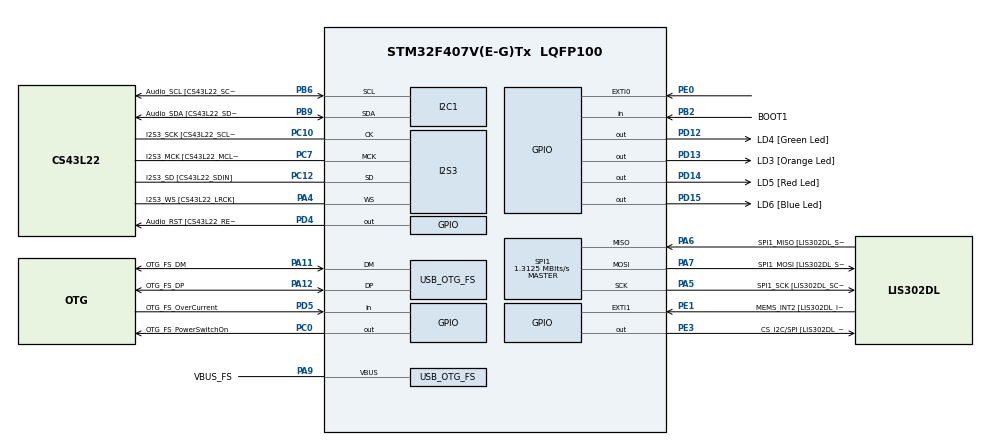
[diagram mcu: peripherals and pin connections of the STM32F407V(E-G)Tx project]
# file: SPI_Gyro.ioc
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FREERTOS.Tasks01=defaultTask,0,128,StartDefaultTask,Default,NULL
I2S3.AudioFreq-Half_Duplex_Master=I2S_AUDIOFREQ_96K
I2S3.ErrorAudioFreq=-2.34 %
I2S3.ErrorAudioFreq-Half_Duplex_Master=0.8 %
I2S3.FullDuplexMode=I2S_FULLDUPLEXMODE_DISABLE
I2S3.Instance=SPI$Index
I2S3.RealAudioFreq=93.75 KHz
I2S3.RealAudioFreq-Half_Duplex_Master=96.774 KHz
I2S3.VirtualMode=I2S_MODE_MASTER
Mcu.Family=STM32F4
Mcu.Name=STM32F407V(E-G)Tx
Mcu.Package=LQFP100
NVIC.EXTI0_IRQn=true\:5\:0\:false\:false\:true\:true\:true
NVIC.OTG_FS_IRQn=true\:5\:0\:false\:false\:true\:true\:true
NVIC.PriorityGroup=NVIC_PRIORITYGROUP_4
NVIC.TIM1_UP_TIM10_IRQn=true\:0\:0\:false\:false\:true\:false\:false
NVIC.TimeBase=TIM1_UP_TIM10_IRQn
NVIC.TimeBaseIP=TIM1
PA10.GPIO_Label=OTG_FS_ID
PA10.GPIO_Mode=GPIO_MODE_AF_PP
PA10.GPIO_PuPd=GPIO_NOPULL
PA10.GPIO_Speed=GPIO_SPEED_FREQ_LOW
PA10.Signal=USB_OTG_FS_ID
PA11.GPIO_Label=OTG_FS_DM
PA11.GPIO_Mode=GPIO_MODE_AF_PP
PA11.GPIO_PuPd=GPIO_NOPULL
PA11.GPIO_Speed=GPIO_SPEED_FREQ_LOW
PA11.Mode=Host_Only
PA11.Signal=USB_OTG_FS_DM
PA12.GPIO_Label=OTG_FS_DP
PA12.GPIO_Mode=GPIO_MODE_AF_PP
PA12.GPIO_PuPd=GPIO_NOPULL
PA12.GPIO_Speed=GPIO_SPEED_FREQ_LOW
PA12.Mode=Host_Only
PA12.Signal=USB_OTG_FS_DP
PA13.GPIO_Label=SWDIO
PA13.Mode=Serial_Wire
PA13.Signal=SYS_JTMS-SWDIO
PA14.GPIO_Label=SWCLK
PA14.Mode=Serial_Wire
PA14.Signal=SYS_JTCK-SWCLK
PA4.GPIO_Label=I2S3_WS [CS43L22_LRCK]
PA4.GPIO_Mode=GPIO_MODE_AF_PP
PA4.GPIO_PuPd=GPIO_NOPULL
PA4.GPIO_Speed=GPIO_SPEED_FREQ_LOW
PA4.Mode=Half_Duplex_Master
PA4.Signal=I2S3_WS
PA5.GPIO_Label=SPI1_SCK [LIS302DL_SCL/SPC]
PA5.GPIO_Mode=GPIO_MODE_AF_PP
PA5.GPIO_PuPd=GPIO_NOPULL
PA5.GPIO_Speed=GPIO_SPEED_FREQ_LOW
PA5.Mode=Full_Duplex_Master
PA5.Signal=SPI1_SCK
PA6.GPIO_Label=SPI1_MISO [LIS302DL_SDO]
PA6.GPIO_Mode=GPIO_MODE_AF_PP
PA6.GPIO_PuPd=GPIO_NOPULL
PA6.GPIO_Speed=GPIO_SPEED_FREQ_LOW
PA6.Mode=Full_Duplex_Master
PA6.Signal=SPI1_MISO
PA7.GPIO_Label=SPI1_MOSI [LIS302DL_SDA/SDI/SDO]
PA7.GPIO_Mode=GPIO_MODE_AF_PP
PA7.GPIO_PuPd=GPIO_NOPULL
PA7.GPIO_Speed=GPIO_SPEED_FREQ_LOW
PA7.Mode=Full_Duplex_Master
PA7.Signal=SPI1_MOSI
PA9.GPIO_Label=VBUS_FS
PA9.GPIO_Mode=GPIO_MODE_INPUT
PA9.GPIO_PuPd=GPIO_NOPULL
PA9.Mode=Activate_VBUS
PA9.Signal=USB_OTG_FS_VBUS
PB10.GPIO_Label=CLK_IN [MP45DT02_CLK]
PB10.GPIO_Mode=GPIO_MODE_AF_PP
PB10.GPIO_PuPd=GPIO_NOPULL
PB10.GPIO_Speed=GPIO_SPEED_FREQ_LOW
PB10.Signal=I2S2_CK
PB2.GPIO_Label=BOOT1
PB2.GPIO_Mode=GPIO_MODE_INPUT
PB2.GPIO_PuPd=GPIO_NOPULL
PB2.Signal=GPIO_Input
PB3.GPIO_Label=SWO
PB3.Signal=SYS_JTDO-SWO
PB6.GPIO_Label=Audio_SCL [CS43L22_SCL]
PB6.GPIO_Mode=GPIO_MODE_AF_OD
PB6.GPIO_PuPd=GPIO_NOPULL
PB6.GPIO_Speed=GPIO_SPEED_FREQ_LOW
PB6.Mode=I2C
PB6.Signal=I2C1_SCL
PB9.GPIO_Label=Audio_SDA [CS43L22_SDA]
PB9.GPIO_Mode=GPIO_MODE_AF_OD
PB9.GPIO_PuPd=GPIO_NOPULL
PB9.GPIO_Speed=GPIO_SPEED_FREQ_LOW
PB9.Mode=I2C
PB9.Signal=I2C1_SDA
PC0.GPIO_Label=OTG_FS_PowerSwitchOn
PC0.GPIO_PuPd=GPIO_NOPULL
PC0.GPIO_Speed=GPIO_SPEED_FREQ_LOW
PC0.PinState=GPIO_PIN_SET
PC0.Signal=GPIO_Output
PC10.GPIO_Label=I2S3_SCK [CS43L22_SCLK]
PC10.GPIO_Mode=GPIO_MODE_AF_PP
PC10.GPIO_PuPd=GPIO_NOPULL
PC10.GPIO_Speed=GPIO_SPEED_FREQ_LOW
PC10.Mode=Half_Duplex_Master
PC10.Signal=I2S3_CK
PC12.GPIO_Label=I2S3_SD [CS43L22_SDIN]
PC12.GPIO_Mode=GPIO_MODE_AF_PP
PC12.GPIO_PuPd=GPIO_NOPULL
PC12.GPIO_Speed=GPIO_SPEED_FREQ_LOW
PC12.Mode=Half_Duplex_Master
PC12.Signal=I2S3_SD
PC14-OSC32_IN.GPIO_Label=PC14-OSC32_IN
PC14-OSC32_IN.Mode=LSE-External-Oscillator
PC14-OSC32_IN.Signal=RCC_OSC32_IN
PC15-OSC32_OUT.GPIO_Label=PC15-OSC32_OUT
PC15-OSC32_OUT.Mode=LSE-External-Oscillator
PC15-OSC32_OUT.Signal=RCC_OSC32_OUT
PC3.GPIO_Label=PDM_OUT [MP45DT02_DOUT]
PC3.GPIO_Mode=GPIO_MODE_AF_PP
PC3.GPIO_PuPd=GPIO_NOPULL
PC3.GPIO_Speed=GPIO_SPEED_FREQ_LOW
PC3.Signal=I2S2_SD
PC7.GPIO_Label=I2S3_MCK [CS43L22_MCLK]
PC7.GPIO_Mode=GPIO_MODE_AF_PP
PC7.GPIO_PuPd=GPIO_NOPULL
PC7.GPIO_Speed=GPIO_SPEED_FREQ_LOW
PC7.Mode=Master_Clock_Activated
PC7.Signal=I2S3_MCK
PD12.GPIO_Label=LD4 [Green Led]
PD12.GPIO_PuPd=GPIO_NOPULL
PD12.GPIO_Speed=GPIO_SPEED_FREQ_LOW
PD12.Signal=GPIO_Output
PD13.GPIO_Label=LD3 [Orange Led]
PD13.GPIO_PuPd=GPIO_NOPULL
PD13.GPIO_Speed=GPIO_SPEED_FREQ_LOW
PD13.Signal=GPIO_Output
PD14.GPIO_Label=LD5 [Red Led]
PD14.GPIO_PuPd=GPIO_NOPULL
PD14.GPIO_Speed=GPIO_SPEED_FREQ_LOW
PD14.Signal=GPIO_Output
PD15.GPIO_Label=LD6 [Blue Led]
PD15.GPIO_PuPd=GPIO_NOPULL
PD15.GPIO_Speed=GPIO_SPEED_FREQ_LOW
PD15.Signal=GPIO_Output
PD4.GPIO_Label=Audio_RST [CS43L22_RESET]
PD4.GPIO_PuPd=GPIO_NOPULL
PD4.GPIO_Speed=GPIO_SPEED_FREQ_LOW
PD4.Signal=GPIO_Output
PD5.GPIO_Label=OTG_FS_OverCurrent
PD5.GPIO_Mode=GPIO_MODE_INPUT
PD5.GPIO_PuPd=GPIO_NOPULL
PD5.Signal=GPIO_Input
PE0.Signal=GPXTI0
PE1.GPIO_Label=MEMS_INT2 [LIS302DL_INT2]
PE1.GPIO_ModeDefaultEXTI=GPIO_MODE_EVT_RISING
PE1.GPIO_PuPd=GPIO_NOPULL
PE1.Signal=GPXTI1
PE3.GPIO_Label=CS_I2C/SPI [LIS302DL_CS_I2C/SPI]
PE3.GPIO_PuPd=GPIO_NOPULL
PE3.GPIO_Speed=GPIO_SPEED_FREQ_LOW
PE3.Signal=GPIO_Output
PH0-OSC_IN.GPIO_Label=PH0-OSC_IN
PH0-OSC_IN.Mode=HSE-External-Oscillator
PH0-OSC_IN.Signal=RCC_OSC_IN
PH1-OSC_OUT.GPIO_Label=PH1-OSC_OUT
PH1-OSC_OUT.Mode=HSE-External-Oscillator
PH1-OSC_OUT.Signal=RCC_OSC_OUT
ProjectManager.HeapSize=0x200
ProjectManager.StackSize=0x400
ProjectManager.TargetToolchain=MDK-ARM V5
RCC.48MHZClocksFreq_Value=48000000
RCC.AHBFreq_Value=168000000
RCC.APB1CLKDivider=RCC_HCLK_DIV4
RCC.APB1Freq_Value=42000000
RCC.APB1TimFreq_Value=84000000
RCC.APB2CLKDivider=RCC_HCLK_DIV2
RCC.APB2Freq_Value=84000000
RCC.APB2TimFreq_Value=168000000
RCC.CortexFreq_Value=168000000
RCC.HCLKFreq_Value=168000000
RCC.HSE_VALUE=8000000
RCC.HSI_VALUE=16000000
RCC.PLLM=8
RCC.PLLN=336
RCC.PLLQ=7
RCC.SYSCLKFreq_VALUE=168000000
RCC.SYSCLKSource=RCC_SYSCLKSOURCE_PLLCLK
RCC.VCOOutputFreq_Value=336000000
SPI1.BaudRatePrescaler=SPI_BAUDRATEPRESCALER_64
SPI1.BaudRatePrescaler-Full_Duplex_Master=SPI_BAUDRATEPRESCALER_2
SPI1.CalculateBaudRate=1.3125 MBits/s
SPI1.CalculateBaudRate-Full_Duplex_Master=42.0 MBits/s
SPI1.Direction=SPI_DIRECTION_2LINES
SPI1.Mode=SPI_MODE_MASTER
SPI1.Mode-Full_Duplex_Master=SPI_MODE_MASTER
SPI1.VirtualType=VM_MASTER
USB_HOST.BSP.number=1
USB_HOST.USBH_HandleTypeDef-CDC_FS=hUsbHostFS
USB_HOST.VirtualModeFS=Cdc
USB_HOST0.BSP.STBoard=false
USB_HOST0.BSP.api=UnknownBspDriver
USB_HOST0.BSP.i2caddr=0
USB_HOST0.BSP.i2creg=0
USB_HOST0.BSP.instance=PC0
USB_HOST0.BSP.ip=GPIO
USB_HOST0.BSP.mode=Output
USB_HOST0.BSP.name=Drive_VBUS_FS
USB_HOST0.BSP.solution=PC0
USB_OTG_FS.VirtualMode=Host_Only
USB_OTG_FS.phy_itface=HCD_PHY_EMBEDDED
VP_FREERTOS_VS_ENABLE.Mode=Enabled
VP_SYS_VS_tim1.Mode=TIM1
VP_USB_HOST_VS_USB_HOST_CDC_FS.Mode=CDC_FS
board=STM32F4DISCOVERY

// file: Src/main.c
/**
  ******************************************************************************
  * @file           : main.c
  * @brief          : Main program body
  ******************************************************************************
  * This notice applies to any and all portions of this file
  * that are not between comment pairs USER CODE BEGIN and
  * USER CODE END. Other portions of this file, whether
  * inserted by the user or by software development tools
  * are owned by their respective copyright owners.
  *
  * Copyright (c) 2019 STMicroelectronics International N.V.
  * All rights reserved.
  *
  * Redistribution and use in source and binary forms, with or without
  * modification, are permitted, provided that the following conditions are met:
  *
  * 1. Redistribution of source code must retain the above copyright notice,
  *    this list of conditions and the following disclaimer.
  * 2. Redistributions in binary form must reproduce the above copyright notice,
  *    this list of conditions and the following disclaimer in the documentation
  *    and/or other materials provided with the distribution.
  * 3. Neither the name of STMicroelectronics nor the names of other
  *    contributors to this software may be used to endorse or promote products
  *    derived from this software without specific written permission.
  * 4. This software, including modifications and/or derivative works of this
  *    software, must execute solely and exclusively on microcontroller or
  *    microprocessor devices manufactured by or for STMicroelectronics.
  * 5. Redistribution and use of this software other than as permitted under
  *    this license is void and will automatically terminate your rights under
  *    this license.
  *
  * THIS SOFTWARE IS PROVIDED BY STMICROELECTRONICS AND CONTRIBUTORS "AS IS"
  * AND ANY EXPRESS, IMPLIED OR STATUTORY WARRANTIES, INCLUDING, BUT NOT
  * LIMITED TO, THE IMPLIED WARRANTIES OF MERCHANTABILITY, FITNESS FOR A
  * PARTICULAR PURPOSE AND NON-INFRINGEMENT OF THIRD PARTY INTELLECTUAL PROPERTY
  * RIGHTS ARE DISCLAIMED TO THE FULLEST EXTENT PERMITTED BY LAW. IN NO EVENT
  * SHALL STMICROELECTRONICS OR CONTRIBUTORS BE LIABLE FOR ANY DIRECT, INDIRECT,
  * INCIDENTAL, SPECIAL, EXEMPLARY, OR CONSEQUENTIAL DAMAGES (INCLUDING, BUT NOT
  * LIMITED TO, PROCUREMENT OF SUBSTITUTE GOODS OR SERVICES; LOSS OF USE, DATA,
  * OR PROFITS; OR BUSINESS INTERRUPTION) HOWEVER CAUSED AND ON ANY THEORY OF
  * LIABILITY, WHETHER IN CONTRACT, STRICT LIABILITY, OR TORT (INCLUDING
  * NEGLIGENCE OR OTHERWISE) ARISING IN ANY WAY OUT OF THE USE OF THIS SOFTWARE,
  * EVEN IF ADVISED OF THE POSSIBILITY OF SUCH DAMAGE.
  *
  ******************************************************************************
  */
#include "main.h"
#include "stm32f4xx_hal.h"
#include "cmsis_os.h"
#include "usb_host.h"

osThreadId defaultTaskHandle;

/* USER CODE BEGIN PV */
/* Private variables ---------------------------------------------------------*/

/* USER CODE END PV */

void SystemClock_Config(void);
extern void MX_GPIO_Init(void);
extern void MX_I2C1_Init(void);
extern void MX_I2S3_Init(void);
extern void MX_SPI1_Init(void);
void StartDefaultTask(void const * argument);

/* USER CODE BEGIN PFP */
/* Private function prototypes -----------------------------------------------*/

/* USER CODE END PFP */

/* USER CODE BEGIN 0 */
void vTaskLED(void *pvParameters);
void vTaskBTN(void *pvParameters);
volatile uint8_t LEDFlag = 0;

/* USER CODE END 0 */

int main(void)
{

  /* MCU Configuration----------------------------------------------------------*/

  /* Reset of all peripherals, Initializes the Flash interface and the Systick. */
  HAL_Init();

  /* Configure the system clock */
  SystemClock_Config();

  /* USER CODE BEGIN SysInit */
	xTaskCreate(	vTaskLED ,		/* Pointer to the function that implements the task. */
						"Task LED",	/* Text name for the task.  This is to facilitate debugging only. */
						240,		/* Stack depth in words. */
						NULL,		/* We are not using the task parameter. */
						1,			/* This task will run at priority 1. */
						NULL );		/* We are not using the task handle. */

		/* Create the other task in exactly the same way. */
	xTaskCreate( vTaskBTN, "Task BTN", 240, NULL, 1, NULL );
  /* USER CODE END SysInit */

  /* Initialize all configured peripherals */
  MX_GPIO_Init();
  MX_I2C1_Init();
  MX_I2S3_Init();
  MX_SPI1_Init();
  /* USER CODE BEGIN 2 */

//Start Segger SystemView trace.
	SEGGER_SYSVIEW_Conf();

  /* Create the thread(s) */
  /* definition and creation of defaultTask */
  osThreadDef(defaultTask, StartDefaultTask, osPriorityNormal, 0, 128);
  defaultTaskHandle = osThreadCreate(osThread(defaultTask), NULL);

  /* Start scheduler */
  osKernelStart();

  /* We should never get here as control is now taken by the scheduler */

  /* Infinite loop */
  /* USER CODE BEGIN WHILE */
  while (1)
  {
  }
  /* USER CODE END 3 */
}

void vTaskLED(void *pvParameters)
{

	for(;;){
	//	if (LEDFlag == 0 )
	//		HAL_GPIO_WritePin(GPIOD,GPIO_PIN_15,GPIO_PIN_SET);
	//	else
	//		HAL_GPIO_WritePin(GPIOD,GPIO_PIN_15,GPIO_PIN_RESET);

		vTaskDelay(100);

	}
}

void vTaskBTN(void *pvParameters)
{

	for(;;){

		HAL_GPIO_TogglePin(GPIOD,GPIO_PIN_14);
		//LEDFlag = HAL_GPIO_ReadPin(GPIOA,GPIO_PIN_0);

		vTaskDelay(100);
	}

}

void HAL_GPIO_EXTI_Callback(uint16_t GPIO_Pin)
{
	int i;
  /* Prevent unused argument(s) compilation warning */
  UNUSED(GPIO_Pin);
  /* NOTE: This function Should not be modified, when the callback is needed,
           the HAL_GPIO_EXTI_Callback could be implemented in the user file
   */

	HAL_GPIO_TogglePin(GPIOD,GPIO_PIN_15);
	for(i=0; i<100;i++);

}

/** Configure pins as
        * Analog
        * Input
        * Output
        * EVENT_OUT
        * EXTI
     PC3   ------> I2S2_SD
     PB10   ------> I2S2_CK
*/

/* StartDefaultTask function */
void StartDefaultTask(void const * argument)
{
  /* init code for USB_HOST */
  MX_USB_HOST_Init();

  for(;;)
  {
    osDelay(1);
  }
}

void HAL_TIM_PeriodElapsedCallback(TIM_HandleTypeDef *htim)
{
  if (htim->Instance == TIM1) {
    HAL_IncTick();
  }
}

void _Error_Handler(char *file, int line)
{
  while(1)
  {
  }
}

/************************ (C) COPYRIGHT STMicroelectronics *****END OF FILE****/
